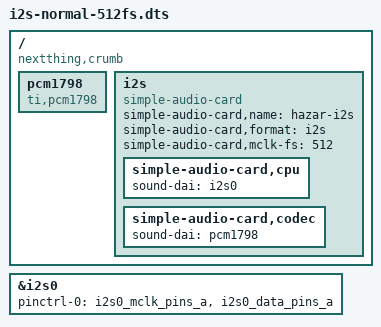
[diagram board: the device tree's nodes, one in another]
/dts-v1/;
/plugin/;

/ {
	compatible = "nextthing,crumb", "nextthing,gr8";
	
	fragment@0 {
        target = <&i2s0>;
        __overlay__ {
            pinctrl-0 = <&i2s0_mclk_pins_a>, <&i2s0_data_pins_a>;
			status = "okay";
        };
    };
	
	fragment@1 {
		target-path = "/";

		__overlay__ {
			pcm1798: pcm1798 {
				compatible = "ti,pcm1798";
				#sound-dai-cells = <0>;
			}; 
			
			i2s {
				compatible = "simple-audio-card";		
				simple-audio-card,name = "hazar-i2s";
				simple-audio-card,format = "i2s";
				simple-audio-card,mclk-fs = <512>;
				
				simple-audio-card,cpu {
					sound-dai = <&i2s0>;
				};

				simple-audio-card,codec {
					sound-dai = <&pcm1798>;
				};
			};
		};
	};
};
